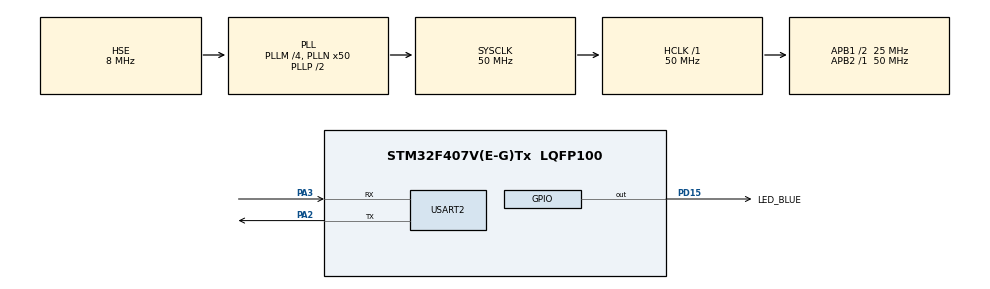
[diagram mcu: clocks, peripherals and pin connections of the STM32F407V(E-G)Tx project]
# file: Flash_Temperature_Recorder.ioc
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ADC1.Channel-0\#ChannelRegularConversion=ADC_CHANNEL_TEMPSENSOR
ADC1.ClockPrescaler=ADC_CLOCK_SYNC_PCLK_DIV4
ADC1.ContinuousConvMode=ENABLE
ADC1.DMAContinuousRequests=ENABLE
ADC1.NbrOfConversionFlag=1
ADC1.Rank-0\#ChannelRegularConversion=1
ADC1.SamplingTime-0\#ChannelRegularConversion=ADC_SAMPLETIME_112CYCLES
ADC1.master=1
Dma.ADC1.0.Direction=DMA_PERIPH_TO_MEMORY
Dma.ADC1.0.FIFOMode=DMA_FIFOMODE_DISABLE
Dma.ADC1.0.Instance=DMA2_Stream0
Dma.ADC1.0.MemDataAlignment=DMA_MDATAALIGN_WORD
Dma.ADC1.0.MemInc=DMA_MINC_ENABLE
Dma.ADC1.0.Mode=DMA_CIRCULAR
Dma.ADC1.0.PeriphDataAlignment=DMA_PDATAALIGN_WORD
Dma.ADC1.0.PeriphInc=DMA_PINC_DISABLE
Dma.ADC1.0.Priority=DMA_PRIORITY_LOW
Dma.Request0=ADC1
Mcu.Family=STM32F4
Mcu.Name=STM32F407V(E-G)Tx
Mcu.Package=LQFP100
NVIC.DMA2_Stream0_IRQn=true\:0\:0\:false\:false\:true\:false\:true\:true
NVIC.PriorityGroup=NVIC_PRIORITYGROUP_0
NVIC.TIM1_UP_TIM10_IRQn=true\:0\:0\:false\:false\:true\:true\:true\:true
PA13.Mode=Serial_Wire
PA13.Signal=SYS_JTMS-SWDIO
PA14.Mode=Serial_Wire
PA14.Signal=SYS_JTCK-SWCLK
PA2.Mode=Asynchronous
PA2.Signal=USART2_TX
PA3.Mode=Asynchronous
PA3.Signal=USART2_RX
PD15.GPIO_Label=LED_BLUE
PD15.Signal=GPIO_Output
PH0-OSC_IN.Mode=HSE-External-Oscillator
PH0-OSC_IN.Signal=RCC_OSC_IN
PH1-OSC_OUT.Mode=HSE-External-Oscillator
PH1-OSC_OUT.Signal=RCC_OSC_OUT
ProjectManager.HeapSize=0x200
ProjectManager.StackSize=0x400
ProjectManager.TargetToolchain=STM32CubeIDE
RCC.48MHZClocksFreq_Value=14285714.285714285
RCC.AHBFreq_Value=50000000
RCC.APB1CLKDivider=RCC_HCLK_DIV2
RCC.APB1Freq_Value=25000000
RCC.APB1TimFreq_Value=50000000
RCC.APB2Freq_Value=50000000
RCC.APB2TimFreq_Value=50000000
RCC.CortexFreq_Value=50000000
RCC.HCLKFreq_Value=50000000
RCC.HSE_VALUE=8000000
RCC.HSI_VALUE=16000000
RCC.LSE_VALUE=32768
RCC.PLLM=4
RCC.PLLN=50
RCC.PLLQ=7
RCC.PLLSourceVirtual=RCC_PLLSOURCE_HSE
RCC.SYSCLKFreq_VALUE=50000000
RCC.SYSCLKSource=RCC_SYSCLKSOURCE_PLLCLK
RCC.VCOOutputFreq_Value=100000000
TIM10.Period=50000
TIM10.Prescaler=1000
USART2.VirtualMode=VM_ASYNC
VP_ADC1_TempSens_Input.Mode=IN-TempSens
VP_TIM10_VS_ClockSourceINT.Mode=Enable_Timer
board=STM32F407G-DISC1

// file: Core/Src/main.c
/* USER CODE BEGIN Header */
/**
  ******************************************************************************
  * @file           : main.c
  * @brief          : Main program body
  ******************************************************************************
  * @attention
  *
  * Copyright (c) 2024 STMicroelectronics.
  * All rights reserved.
  *
  * This software is licensed under terms that can be found in the LICENSE file
  * in the root directory of this software component.
  * If no LICENSE file comes with this software, it is provided AS-IS.
  *
  ******************************************************************************
  */
/* USER CODE END Header */
#include "main.h"

/* USER CODE BEGIN Includes */

#include "stdlib.h"
#include "stdio.h"

/* USER CODE END Includes */

ADC_HandleTypeDef hadc1;
DMA_HandleTypeDef hdma_adc1;

TIM_HandleTypeDef htim10;

UART_HandleTypeDef huart2;

/* USER CODE BEGIN PV */
char uart_buf[50];
int uart_buf_len;
uint16_t timer_val;
double rx_buffer[20];
double tx_buffer[20];
uint8_t count = 0;
float temp = 0;
uint32_t adc_val = 0;
/* USER CODE END PV */

void SystemClock_Config(void);
static void MX_GPIO_Init(void);
static void MX_DMA_Init(void);
static void MX_ADC1_Init(void);
static void MX_USART2_UART_Init(void);
static void MX_TIM10_Init(void);
/* USER CODE BEGIN PFP */

uint32_t FlashWrite(uint32_t sector_address, double * data)
{
	uint32_t SECTORError;
	static FLASH_EraseInitTypeDef EraseInitStruct;
	uint8_t count = 0;

	HAL_FLASH_Unlock();

	  EraseInitStruct.TypeErase     = FLASH_TYPEERASE_SECTORS;
	  EraseInitStruct.VoltageRange  = FLASH_VOLTAGE_RANGE_3;
	  EraseInitStruct.Sector        = FLASH_SECTOR_5;
	  EraseInitStruct.NbSectors     = 1;

	  if (HAL_FLASHEx_Erase(&EraseInitStruct, &SECTORError) != HAL_OK)
	  {
		  return HAL_FLASH_GetError();
	  }

	  while( count < 20 )
	  {
		     if (HAL_FLASH_Program(FLASH_TYPEPROGRAM_WORD, sector_address, data[count]) == HAL_OK)
		     {
		    	 sector_address += 8;  // use StartPageAddress += 2 for half word and 8 for double word
		    	 count++;
		     }
		     else
		     {
		       /* Error occurred while writing data in Flash memory*/
		    	 return HAL_FLASH_GetError ();
		     }

	  }

	  HAL_FLASH_Lock();

	  return 0;
}

void FlashRead (uint32_t sector_address, double *buffer)
{
	uint8_t count = 0 ;

	while (count < 20)
	{

		*buffer = *(__IO uint32_t *)sector_address;
		sector_address += 8;
		buffer++;
		count++;
	}
}

void TIM_IRQ_Handler(TIM_HandleTypeDef *htim)
{
	if( (count < 20) && (adc_val != 0) )
	{
	  tx_buffer[count] = temp;
	  count++;

	  uart_buf_len = sprintf(uart_buf, "Data Written --  %d C \r\n",  (int)temp);
	  HAL_UART_Transmit(&huart2, (uint8_t *)uart_buf, uart_buf_len, 100);
	}
	else if(count == 20)
	{
		FlashWrite(0x08020000, tx_buffer);
		count++;
	}
}

/* USER CODE END PFP */

/* USER CODE BEGIN 0 */

#define AVG_SLOPE		0.0025			// V/C
#define V_25C			0.76			// V
#define V_SENSE			(3.0/4096) 		// for 12 bit resolution

void HAL_ADC_ConvCpltCallback(ADC_HandleTypeDef *hadc)
{
	temp = (( (adc_val*V_SENSE) - V_25C ) / AVG_SLOPE ) + 25;
}

/* USER CODE END 0 */

int main(void)
{

  /* MCU Configuration--------------------------------------------------------*/

  /* Reset of all peripherals, Initializes the Flash interface and the Systick. */
  HAL_Init();

  /* Configure the system clock */
  SystemClock_Config();

  /* Initialize all configured peripherals */
  MX_GPIO_Init();
  MX_DMA_Init();
  MX_ADC1_Init();
  MX_USART2_UART_Init();
  MX_TIM10_Init();
  /* USER CODE BEGIN 2 */
  FlashRead(0x08020000, rx_buffer);
  for(int i = 0; i<20; i++)
  {
	  uart_buf_len = sprintf(uart_buf, "Data Read --  %d C \r\n",  (int)rx_buffer[i]);
	  HAL_UART_Transmit(&huart2, (uint8_t *)uart_buf, uart_buf_len, 100);
  }

  HAL_Delay(5000);

  HAL_ADC_Start_DMA(&hadc1, &adc_val, 1);
  HAL_TIM_Base_Start(&htim10);

  /* USER CODE END 2 */

  /* Infinite loop */
  while (1)
  {

  }
}

void SystemClock_Config(void)
{
  RCC_OscInitTypeDef RCC_OscInitStruct = {0};
  RCC_ClkInitTypeDef RCC_ClkInitStruct = {0};

  /** Configure the main internal regulator output voltage
  */
  __HAL_RCC_PWR_CLK_ENABLE();
  __HAL_PWR_VOLTAGESCALING_CONFIG(PWR_REGULATOR_VOLTAGE_SCALE1);

  /** Initializes the RCC Oscillators according to the specified parameters
  * in the RCC_OscInitTypeDef structure.
  */
  RCC_OscInitStruct.OscillatorType = RCC_OSCILLATORTYPE_HSE;
  RCC_OscInitStruct.HSEState = RCC_HSE_ON;
  RCC_OscInitStruct.PLL.PLLState = RCC_PLL_ON;
  RCC_OscInitStruct.PLL.PLLSource = RCC_PLLSOURCE_HSE;
  RCC_OscInitStruct.PLL.PLLM = 4;
  RCC_OscInitStruct.PLL.PLLN = 50;
  RCC_OscInitStruct.PLL.PLLP = RCC_PLLP_DIV2;
  RCC_OscInitStruct.PLL.PLLQ = 7;
  if (HAL_RCC_OscConfig(&RCC_OscInitStruct) != HAL_OK)
  {
    Error_Handler();
  }

  /** Initializes the CPU, AHB and APB buses clocks
  */
  RCC_ClkInitStruct.ClockType = RCC_CLOCKTYPE_HCLK|RCC_CLOCKTYPE_SYSCLK
                              |RCC_CLOCKTYPE_PCLK1|RCC_CLOCKTYPE_PCLK2;
  RCC_ClkInitStruct.SYSCLKSource = RCC_SYSCLKSOURCE_PLLCLK;
  RCC_ClkInitStruct.AHBCLKDivider = RCC_SYSCLK_DIV1;
  RCC_ClkInitStruct.APB1CLKDivider = RCC_HCLK_DIV2;
  RCC_ClkInitStruct.APB2CLKDivider = RCC_HCLK_DIV1;

  if (HAL_RCC_ClockConfig(&RCC_ClkInitStruct, FLASH_LATENCY_1) != HAL_OK)
  {
    Error_Handler();
  }
}

static void MX_ADC1_Init(void)
{

  ADC_ChannelConfTypeDef sConfig = {0};

  /** Configure the global features of the ADC (Clock, Resolution, Data Alignment and number of conversion)
  */
  hadc1.Instance = ADC1;
  hadc1.Init.ClockPrescaler = ADC_CLOCK_SYNC_PCLK_DIV4;
  hadc1.Init.Resolution = ADC_RESOLUTION_12B;
  hadc1.Init.ScanConvMode = DISABLE;
  hadc1.Init.ContinuousConvMode = ENABLE;
  hadc1.Init.DiscontinuousConvMode = DISABLE;
  hadc1.Init.ExternalTrigConvEdge = ADC_EXTERNALTRIGCONVEDGE_NONE;
  hadc1.Init.ExternalTrigConv = ADC_SOFTWARE_START;
  hadc1.Init.DataAlign = ADC_DATAALIGN_RIGHT;
  hadc1.Init.NbrOfConversion = 1;
  hadc1.Init.DMAContinuousRequests = ENABLE;
  hadc1.Init.EOCSelection = ADC_EOC_SINGLE_CONV;
  if (HAL_ADC_Init(&hadc1) != HAL_OK)
  {
    Error_Handler();
  }

  /** Configure for the selected ADC regular channel its corresponding rank in the sequencer and its sample time.
  */
  sConfig.Channel = ADC_CHANNEL_TEMPSENSOR;
  sConfig.Rank = 1;
  sConfig.SamplingTime = ADC_SAMPLETIME_112CYCLES;
  if (HAL_ADC_ConfigChannel(&hadc1, &sConfig) != HAL_OK)
  {
    Error_Handler();
  }

}

static void MX_TIM10_Init(void)
{

  htim10.Instance = TIM10;
  htim10.Init.Prescaler = 1000;
  htim10.Init.CounterMode = TIM_COUNTERMODE_UP;
  htim10.Init.Period = 50000;
  htim10.Init.ClockDivision = TIM_CLOCKDIVISION_DIV1;
  htim10.Init.AutoReloadPreload = TIM_AUTORELOAD_PRELOAD_DISABLE;
  if (HAL_TIM_Base_Init(&htim10) != HAL_OK)
  {
    Error_Handler();
  }
  /* USER CODE BEGIN TIM10_Init 2 */

  TIM10->CR1 |= TIM_CR1_URS;
  TIM10->DIER |= TIM_DIER_UIE;
  TIM10->EGR |= TIM_EGR_UG;

  NVIC_EnableIRQ(TIM1_UP_TIM10_IRQn);
  /* USER CODE END TIM10_Init 2 */

}

static void MX_USART2_UART_Init(void)
{

  huart2.Instance = USART2;
  huart2.Init.BaudRate = 115200;
  huart2.Init.WordLength = UART_WORDLENGTH_8B;
  huart2.Init.StopBits = UART_STOPBITS_1;
  huart2.Init.Parity = UART_PARITY_NONE;
  huart2.Init.Mode = UART_MODE_TX_RX;
  huart2.Init.HwFlowCtl = UART_HWCONTROL_NONE;
  huart2.Init.OverSampling = UART_OVERSAMPLING_16;
  if (HAL_UART_Init(&huart2) != HAL_OK)
  {
    Error_Handler();
  }

}

static void MX_DMA_Init(void)
{

  /* DMA controller clock enable */
  __HAL_RCC_DMA2_CLK_ENABLE();

  /* DMA interrupt init */
  /* DMA2_Stream0_IRQn interrupt configuration */
  HAL_NVIC_SetPriority(DMA2_Stream0_IRQn, 0, 0);
  HAL_NVIC_EnableIRQ(DMA2_Stream0_IRQn);

}

static void MX_GPIO_Init(void)
{
  GPIO_InitTypeDef GPIO_InitStruct = {0};

  /* GPIO Ports Clock Enable */
  __HAL_RCC_GPIOH_CLK_ENABLE();
  __HAL_RCC_GPIOA_CLK_ENABLE();
  __HAL_RCC_GPIOD_CLK_ENABLE();

  /*Configure GPIO pin Output Level */
  HAL_GPIO_WritePin(LED_BLUE_GPIO_Port, LED_BLUE_Pin, GPIO_PIN_RESET);

  /*Configure GPIO pin : LED_BLUE_Pin */
  GPIO_InitStruct.Pin = LED_BLUE_Pin;
  GPIO_InitStruct.Mode = GPIO_MODE_OUTPUT_PP;
  GPIO_InitStruct.Pull = GPIO_NOPULL;
  GPIO_InitStruct.Speed = GPIO_SPEED_FREQ_LOW;
  HAL_GPIO_Init(LED_BLUE_GPIO_Port, &GPIO_InitStruct);

}

void Error_Handler(void)
{
  __disable_irq();
  while (1)
  {
  }
}
